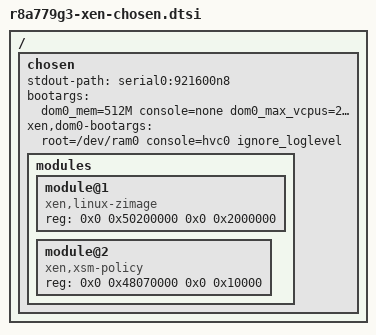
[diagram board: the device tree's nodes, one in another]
/*
 * Device Tree default chosen node for systems running XEN hypervisor
 *
 * Copyright (C) 2021 EPAM Systems.
 *
 * This file is licensed under the terms of the GNU General Public License
 * version 2.  This program is licensed "as is" without any warranty of any
 * kind, whether express or implied.
 */


/ {
	chosen {
		stdout-path = "serial0:921600n8";
		bootargs = "dom0_mem=512M console=none dom0_max_vcpus=2 loglvl=all xsm=flask flask=permissive bootscrub=0 gnttab_max_frames=512";
		xen,dom0-bootargs = "root=/dev/ram0 console=hvc0 ignore_loglevel";
		modules {
			#address-cells = <2>;
			#size-cells = <2>;
			module@1 {
				compatible = "xen,linux-zimage", "xen,multiboot-module";
				reg = <0x0 0x50200000 0x0 0x2000000>;
			};
			module@2 {
				compatible = "xen,xsm-policy", "xen,multiboot-module";
				reg = <0x0 0x48070000 0x0 0x10000>;
			};
		};
	};
};
